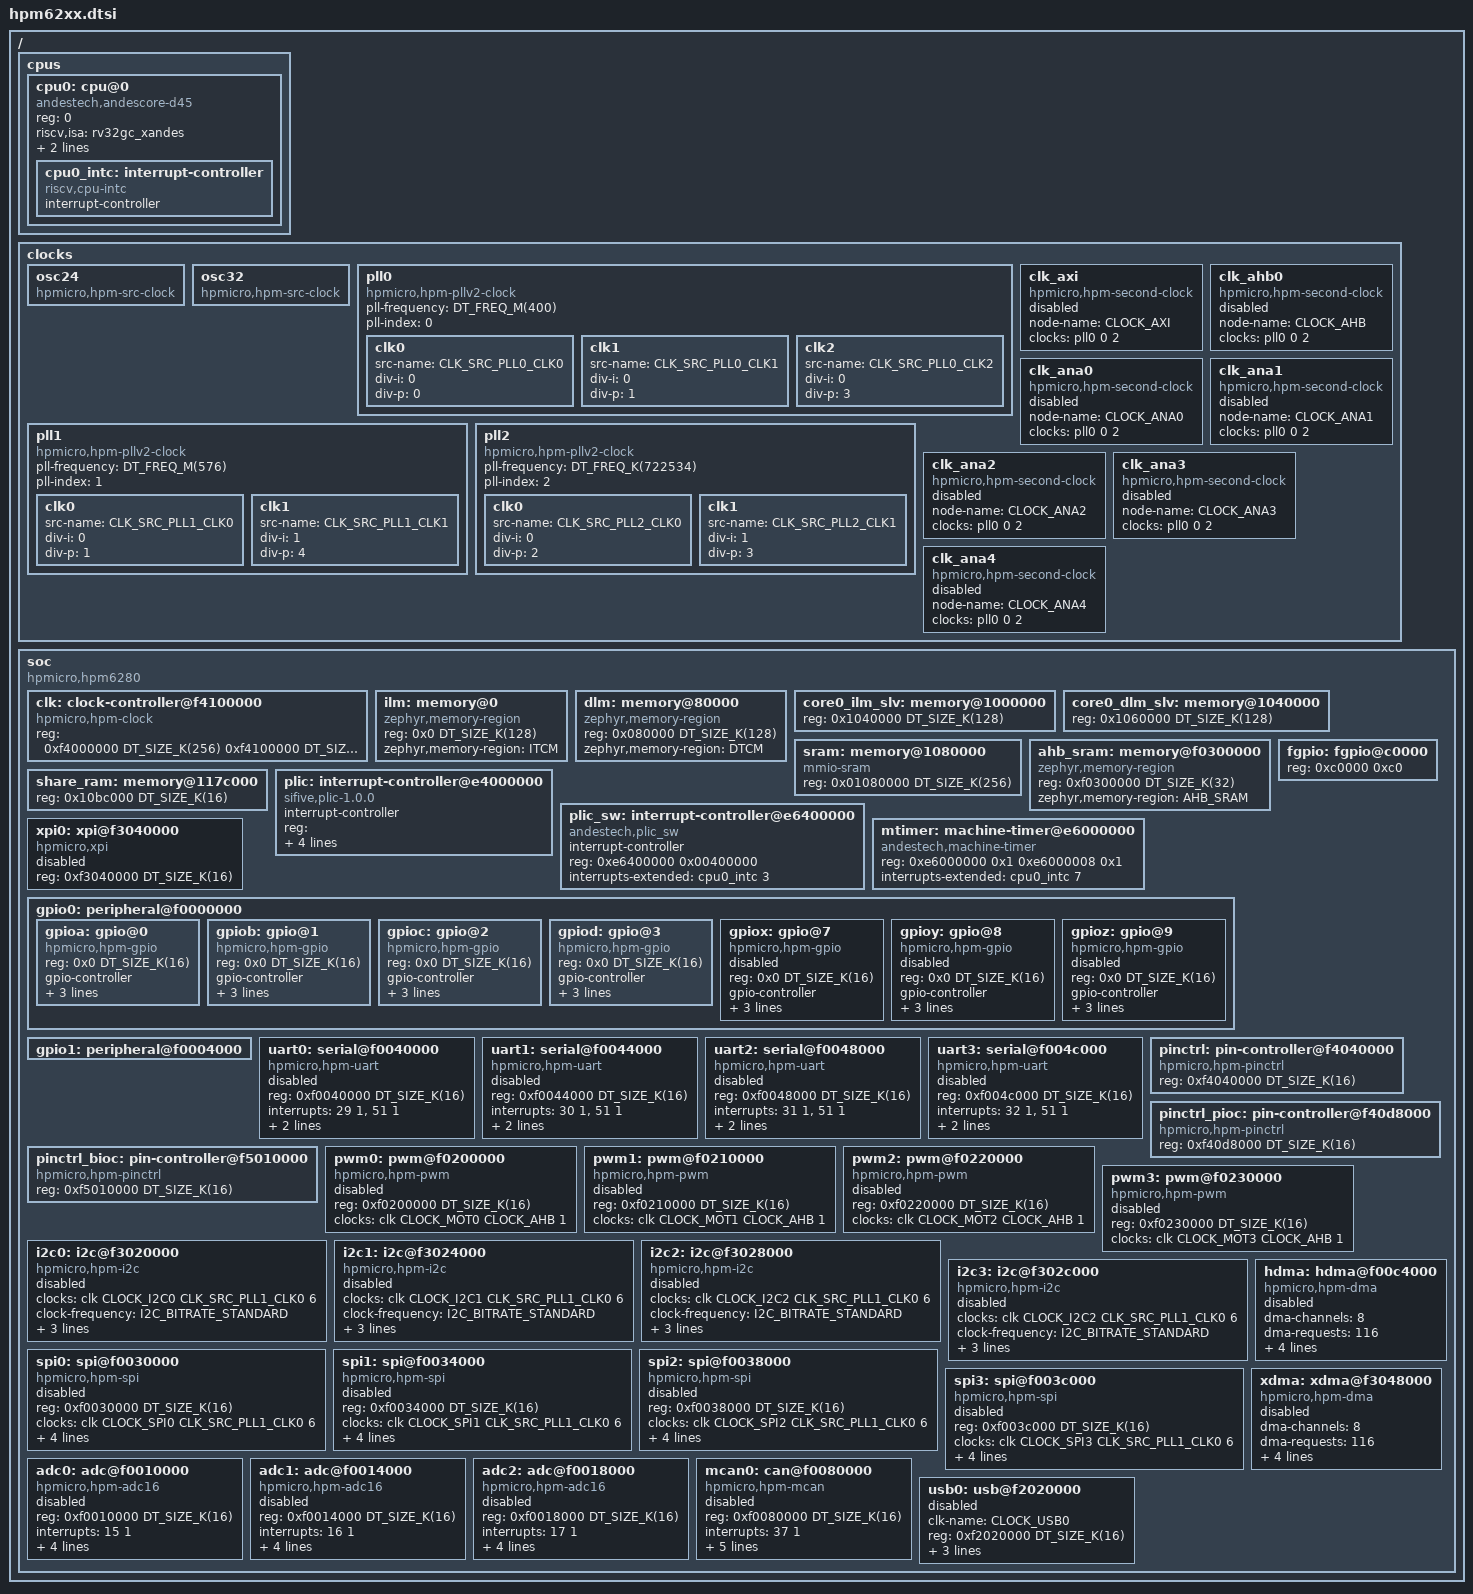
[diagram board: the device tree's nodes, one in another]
/*
 * Copyright 2023-2025 HPMicro
 * SPDX-License-Identifier: Apache-2.0
 */

/dts-v1/;
#include <zephyr/dt-bindings/gpio/gpio.h>
#include <zephyr/dt-bindings/i2c/i2c.h>
#include <zephyr/dt-bindings/pwm/pwm.h>
#include <dt-bindings/pwm/hpmicro-pwm-common.h>
#include <dt-bindings/clock/hpm6280-clocks.h>
#include <mem.h>
#include <freq.h>

/ {
    #address-cells = <1>;
    #size-cells = <1>;

    cpus {
        #address-cells = <1>;
        #size-cells = <0>;
        cpu0: cpu@0 {
            compatible = "andestech,andescore-d45", "riscv";
            reg = <0>;
            status = "okay";
            riscv,isa = "rv32gc_xandes";
            i-cache-line-size = <64>;
            d-cache-line-size = <64>;

            cpu0_intc: interrupt-controller {
                compatible = "riscv,cpu-intc";
                #address-cells = <0>;
                #interrupt-cells = <1>;
                interrupt-controller;
            };
        };
    };

    clocks {
        osc24: osc24 {
            #clock-cells = <2>;
            compatible = "hpmicro,hpm-src-clock";
        };

        osc32: osc32 {
            #clock-cells = <2>;
            compatible = "hpmicro,hpm-src-clock";
        };

        pll0: pll0 {
            #clock-cells = <2>;
            compatible = "hpmicro,hpm-pllv2-clock";
            pll-frequency = <DT_FREQ_M(400)>;
            pll-index = <0>;

            clk0 {
                src-name = <CLK_SRC_PLL0_CLK0>;
                div-i = <0>;
                div-p = <0>;
            };

            clk1 {
                src-name = <CLK_SRC_PLL0_CLK1>;
                div-i = <0>;
                div-p = <1>;
            };

            clk2 {
                src-name = <CLK_SRC_PLL0_CLK2>;
                div-i = <0>;
                div-p = <3>;
            };
        };

        pll1: pll1 {
            #clock-cells = <2>;
            compatible = "hpmicro,hpm-pllv2-clock";
            pll-frequency = <DT_FREQ_M(576)>;
            pll-index = <1>;

            clk0 {
                src-name = <CLK_SRC_PLL1_CLK0>;
                div-i = <0>;
                div-p = <1>;
            };

            clk1 {
                src-name = <CLK_SRC_PLL1_CLK1>;
                div-i = <1>;
                div-p = <4>;
            };
        };

        pll2: pll2 {
            #clock-cells = <2>;
            compatible = "hpmicro,hpm-pllv2-clock";
            pll-frequency = <DT_FREQ_K(722534)>;
            pll-index = <2>;

            clk0 {
                src-name = <CLK_SRC_PLL2_CLK0>;
                div-i = <0>;
                div-p = <2>;
            };

            clk1 {
                src-name = <CLK_SRC_PLL2_CLK1>;
                div-i = <1>;
                div-p = <3>;
            };
        };

        clk_axi: clk_axi {
            #clock-cells = <2>;
            compatible = "hpmicro,hpm-second-clock";
            node-name = <CLOCK_AXI>;
            clocks = <&pll0 0 2>;
            status = "disabled";
        };

        clk_ahb0: clk_ahb0 {
            #clock-cells = <2>;
            compatible = "hpmicro,hpm-second-clock";
            node-name = <CLOCK_AHB>;
            clocks = <&pll0 0 2>;
            status = "disabled";
        };

        clk_ana0: clk_ana0 {
            #clock-cells = <2>;
            compatible = "hpmicro,hpm-second-clock";
            node-name = <CLOCK_ANA0>;
            clocks = <&pll0 0 2>;
            status = "disabled";
        };

        clk_ana1: clk_ana1 {
            #clock-cells = <2>;
            compatible = "hpmicro,hpm-second-clock";
            node-name = <CLOCK_ANA1>;
            clocks = <&pll0 0 2>;
            status = "disabled";
        };

        clk_ana2: clk_ana2 {
            #clock-cells = <2>;
            compatible = "hpmicro,hpm-second-clock";
            node-name = <CLOCK_ANA2>;
            clocks = <&pll0 0 2>;
            status = "disabled";
        };

        clk_ana3: clk_ana3 {
            #clock-cells = <2>;
            compatible = "hpmicro,hpm-second-clock";
            node-name = <CLOCK_ANA3>;
            clocks = <&pll0 0 2>;
            status = "disabled";
        };

        clk_ana4: clk_ana4 {
            #clock-cells = <2>;
            compatible = "hpmicro,hpm-second-clock";
            node-name = <CLOCK_ANA4>;
            clocks = <&pll0 0 2>;
            status = "disabled";
        };
    };

    soc {
        #address-cells = <1>;
        #size-cells = <1>;
        compatible = "hpmicro,hpm6280";
        ranges;

        clk: clock-controller@f4100000 {
            compatible = "hpmicro,hpm-clock";
            reg = <0xf4000000 DT_SIZE_K(256)
                0xf4100000 DT_SIZE_K(16)>;
            reg-names = "sysctl", "pllv2";
            status = "okay";
            #clock-cells = <3>;
        };

        ilm: memory@0 {
            compatible = "zephyr,memory-region";
            reg = <0x0 DT_SIZE_K(128)>;
            zephyr,memory-region = "ITCM";
        };

        dlm: memory@80000 {
            compatible = "zephyr,memory-region";
            reg = <0x080000 DT_SIZE_K(128)>;
            zephyr,memory-region = "DTCM";
        };

        core0_ilm_slv: memory@1000000 {
            reg = <0x1040000 DT_SIZE_K(128)>;
        };

        core0_dlm_slv: memory@1040000 {
            reg = <0x1060000 DT_SIZE_K(128)>;
        };

        sram: memory@1080000 {
            compatible = "mmio-sram";
            reg = <0x01080000 DT_SIZE_K(256)>;
        };

        ahb_sram: memory@f0300000 {
            compatible = "zephyr,memory-region";
            reg = <0xf0300000 DT_SIZE_K(32)>;
            zephyr,memory-region = "AHB_SRAM";
        };

        share_ram: memory@117c000 {
            reg = <0x10bc000 DT_SIZE_K(16)>;
        };

        plic: interrupt-controller@e4000000 {
            compatible = "sifive,plic-1.0.0";
            #address-cells = <1>;
            #interrupt-cells = <2>;
            interrupt-controller;
            reg = <    0xe4000000 0x00001000
                0xe4002000 0x00000800
                0xe4200000 0x00010000 >;
            reg-names = "prio", "irq_en", "reg";
            riscv,max-priority = <255>;
            riscv,ndev = <1023>;
            interrupts-extended = <&cpu0_intc 11>;
        };

        plic_sw: interrupt-controller@e6400000 {
            compatible = "andestech,plic_sw";
            #address-cells = <1>;
            #interrupt-cells = <2>;
            interrupt-controller;
            reg = <0xe6400000 0x00400000>;
            interrupts-extended = <&cpu0_intc 3>;
        };

        mtimer: machine-timer@e6000000 {
            compatible = "andestech,machine-timer";
            reg = <0xe6000000 0x1
            0xe6000008 0x1>;
            interrupts-extended = <&cpu0_intc 7>;
        };

        fgpio: fgpio@c0000 {
            reg = <0xc0000 0xc0>;
        };

        xpi0: xpi@f3040000 {
            compatible = "hpmicro,xpi";
            reg = <0xf3040000 DT_SIZE_K(16)>;
            #address-cells = <1>;
            #size-cells = <1>;
            status = "disabled";
        };

        gpio0: peripheral@f0000000 {
            #address-cells = <1>;
            #size-cells = <1>;
            ranges = <0x0 0xf0000000 DT_SIZE_K(16)>;
        };

        gpio1: peripheral@f0004000 {
            #address-cells = <1>;
            #size-cells = <1>;
            ranges = <0x0 0xf0004000 DT_SIZE_K(16)>;
        };

        uart0: serial@f0040000 {
            compatible = "hpmicro,hpm-uart";
            reg = <0xf0040000 DT_SIZE_K(16)>;
            interrupts = <29 1>, <51 1>;
            interrupt-names = "uart", "idletimer";
            clocks = <&clk CLOCK_UART0 CLK_SRC_PLL1_CLK0 6>;
            interrupt-parent = <&plic>;
            status = "disabled";
        };

        uart1: serial@f0044000 {
            compatible = "hpmicro,hpm-uart";
            reg = <0xf0044000 DT_SIZE_K(16)>;
            interrupts = <30 1>, <51 1>;
            interrupt-names = "uart", "idletimer";
            clocks = <&clk CLOCK_UART1 CLK_SRC_PLL1_CLK0 6>;
            interrupt-parent = <&plic>;
            status = "disabled";
        };

        uart2: serial@f0048000 {
            compatible = "hpmicro,hpm-uart";
            reg = <0xf0048000 DT_SIZE_K(16)>;
            interrupts = <31 1>, <51 1>;
            interrupt-names = "uart", "idletimer";
            clocks = <&clk CLOCK_UART2 CLK_SRC_PLL1_CLK0 6>;
            interrupt-parent = <&plic>;
            status = "disabled";
        };

        uart3: serial@f004c000 {
            compatible = "hpmicro,hpm-uart";
            reg = <0xf004c000 DT_SIZE_K(16)>;
            interrupts = <32 1>, <51 1>;
            interrupt-names = "uart", "idletimer";
            clocks = <&clk CLOCK_UART3 CLK_SRC_PLL1_CLK0 6>;
            interrupt-parent = <&plic>;
            status = "disabled";
        };

        pinctrl: pin-controller@f4040000 {
            compatible = "hpmicro,hpm-pinctrl";
            reg = <0xf4040000 DT_SIZE_K(16)>;
            status = "okay";
        };

        pinctrl_pioc: pin-controller@f40d8000 {
            compatible = "hpmicro,hpm-pinctrl";
            reg = <0xf40d8000 DT_SIZE_K(16)>;
            status = "okay";
        };

        pinctrl_bioc: pin-controller@f5010000 {
            compatible = "hpmicro,hpm-pinctrl";
            reg = <0xf5010000 DT_SIZE_K(16)>;
            status = "okay";
        };

        pwm0: pwm@f0200000 {
            compatible = "hpmicro,hpm-pwm";
            reg = <0xf0200000 DT_SIZE_K(16)>;
            clocks = <&clk CLOCK_MOT0 CLOCK_AHB 1>;
            status = "disabled";
            #pwm-cells = <3>;
        };

        pwm1: pwm@f0210000 {
            compatible = "hpmicro,hpm-pwm";
            reg = <0xf0210000 DT_SIZE_K(16)>;
            clocks = <&clk CLOCK_MOT1 CLOCK_AHB 1>;
            status = "disabled";
            #pwm-cells = <3>;
        };

        pwm2: pwm@f0220000 {
            compatible = "hpmicro,hpm-pwm";
            reg = <0xf0220000 DT_SIZE_K(16)>;
            clocks = <&clk CLOCK_MOT2 CLOCK_AHB 1>;
            status = "disabled";
            #pwm-cells = <3>;
        };

        pwm3: pwm@f0230000 {
            compatible = "hpmicro,hpm-pwm";
            reg = <0xf0230000 DT_SIZE_K(16)>;
            clocks = <&clk CLOCK_MOT3 CLOCK_AHB 1>;
            status = "disabled";
            #pwm-cells = <3>;
        };

        i2c0: i2c@f3020000 {
            compatible = "hpmicro,hpm-i2c";
            #address-cells = <1>;
            #size-cells = <0>;
            clocks = <&clk CLOCK_I2C0 CLK_SRC_PLL1_CLK0 6>;
            clock-frequency = <I2C_BITRATE_STANDARD>;
            reg = <0xf3020000 DT_SIZE_K(16)>;
            interrupts = <53 1>;
            interrupt-parent = <&plic>;
            status = "disabled";
        };

        i2c1: i2c@f3024000 {
            compatible = "hpmicro,hpm-i2c";
            #address-cells = <1>;
            #size-cells = <0>;
            clocks = <&clk CLOCK_I2C1 CLK_SRC_PLL1_CLK0 6>;
            clock-frequency = <I2C_BITRATE_STANDARD>;
            reg = <0xf3024000 DT_SIZE_K(16)>;
            interrupts = <54 1>;
            interrupt-parent = <&plic>;
            status = "disabled";
        };

        i2c2: i2c@f3028000 {
            compatible = "hpmicro,hpm-i2c";
            #address-cells = <1>;
            #size-cells = <0>;
            clocks = <&clk CLOCK_I2C2 CLK_SRC_PLL1_CLK0 6>;
            clock-frequency = <I2C_BITRATE_STANDARD>;
            reg = <0xf3028000 DT_SIZE_K(16)>;
            interrupts = <55 1>;
            interrupt-parent = <&plic>;
            status = "disabled";
        };

        i2c3: i2c@f302c000 {
            compatible = "hpmicro,hpm-i2c";
            #address-cells = <1>;
            #size-cells = <0>;
            clocks = <&clk CLOCK_I2C2 CLK_SRC_PLL1_CLK0 6>;
            clock-frequency = <I2C_BITRATE_STANDARD>;
            reg = <0xf302c000 DT_SIZE_K(16)>;
            interrupts = <56 1>;
            interrupt-parent = <&plic>;
            status = "disabled";
        };

        spi0: spi@f0030000 {
            compatible = "hpmicro,hpm-spi";
            reg = <0xf0030000 DT_SIZE_K(16)>;
            clocks = <&clk CLOCK_SPI0 CLK_SRC_PLL1_CLK0 6>;
            interrupts = <25 1>;
            interrupt-parent = <&plic>;
            status = "disabled";
            #address-cells = <1>;
            #size-cells = <0>;
            cs-sck-delay = <3>;
            cs-minimum-high-time = <11>;
        };

        spi1: spi@f0034000 {
            compatible = "hpmicro,hpm-spi";
            reg = <0xf0034000 DT_SIZE_K(16)>;
            clocks = <&clk CLOCK_SPI1 CLK_SRC_PLL1_CLK0 6>;
            interrupts = <26 1>;
            interrupt-parent = <&plic>;
            status = "disabled";
            #address-cells = <1>;
            #size-cells = <0>;
            cs-sck-delay = <3>;
            cs-minimum-high-time = <11>;
        };

        spi2: spi@f0038000 {
            compatible = "hpmicro,hpm-spi";
            reg = <0xf0038000 DT_SIZE_K(16)>;
            clocks = <&clk CLOCK_SPI2 CLK_SRC_PLL1_CLK0 6>;
            interrupts = <27 1>;
            interrupt-parent = <&plic>;
            status = "disabled";
            #address-cells = <1>;
            #size-cells = <0>;
            cs-sck-delay = <3>;
            cs-minimum-high-time = <11>;
        };


        spi3: spi@f003c000 {
            compatible = "hpmicro,hpm-spi";
            reg = <0xf003c000 DT_SIZE_K(16)>;
            clocks = <&clk CLOCK_SPI3 CLK_SRC_PLL1_CLK0 6>;
            interrupts = <28 1>;
            interrupt-parent = <&plic>;
            status = "disabled";
            #address-cells = <1>;
            #size-cells = <0>;
            cs-sck-delay = <3>;
            cs-minimum-high-time = <11>;
        };

        hdma: hdma@f00c4000 {
            #dma-cells = <2>;
            compatible = "hpmicro,hpm-dma";
            dma-channels = <8>;
            dma-requests = <116>;
            reg = <0xf00c4000 DT_SIZE_K(16)>,
                <0xf00c0000 DT_SIZE_K(16)>; /* DMAMUX base */
            interrupts = <72 1>;
            interrupt-parent = <&plic>;
            status = "disabled";
        };

        xdma: xdma@f3048000 {
            #dma-cells = <2>;
            compatible = "hpmicro,hpm-dma";
            dma-channels = <8>;
            dma-requests = <116>;
            reg = <0xf3048000 DT_SIZE_K(16)>,
                <0xf00c0000 DT_SIZE_K(16)>; /* DMAMUX base */
            interrupts = <71 1>;
            interrupt-parent = <&plic>;
            status = "disabled";
        };

        adc0: adc@f0010000 {
            compatible = "hpmicro,hpm-adc16";
            reg = <0xf0010000 DT_SIZE_K(16)>;
            interrupts = <15 1>;
            interrupt-parent = <&plic>;
            clocks = <&clk CLOCK_ADC0 CLK_ADC_SRC_ANA0 1>, <&clk CLOCK_ANA0 CLK_SRC_PLL0_CLK0 2>;
            sample-time = <20>;
            status = "disabled";
            #io-channel-cells = <1>;
        };

        adc1: adc@f0014000 {
            compatible = "hpmicro,hpm-adc16";
            reg = <0xf0014000 DT_SIZE_K(16)>;
            interrupts = <16 1>;
            interrupt-parent = <&plic>;
            clocks = <&clk CLOCK_ADC1 CLK_ADC_SRC_ANA1 1>, <&clk CLOCK_ANA1 CLK_SRC_PLL0_CLK0 2>;
            sample-time = <20>;
            status = "disabled";
            #io-channel-cells = <1>;
        };

        adc2: adc@f0018000 {
            compatible = "hpmicro,hpm-adc16";
            reg = <0xf0018000 DT_SIZE_K(16)>;
            interrupts = <17 1>;
            interrupt-parent = <&plic>;
            clocks = <&clk CLOCK_ADC2 CLK_ADC_SRC_ANA2 1>, <&clk CLOCK_ANA2 CLK_SRC_PLL0_CLK0 2>;
            sample-time = <20>;
            status = "disabled";
            #io-channel-cells = <1>;
        };

        mcan0: can@f0080000 {
                compatible = "hpmicro,hpm-mcan";
                reg = <0xf0080000 DT_SIZE_K(16)>;
                interrupts = <37 1>;
                interrupt-parent = <&plic>;
                clk-name = <CLOCK_CAN0>;
                clk-source = <CLK_SRC_PLL1_CLK0>;
                clk-divider = <5>;
                bus-speed = <500000>;
                status = "disabled";
        };

        usb0: usb@f2020000 {
                clk-name = <CLOCK_USB0>;
                reg = <0xf2020000 DT_SIZE_K(16)>;
                interrupts = <74 1>;
                interrupt-parent = <&plic>;
                num-bidir-endpoints = <8>;
                status = "disabled";
        };
    };
};

&gpio0 {
    gpioa: gpio@0 {
        compatible = "hpmicro,hpm-gpio";
        reg = <0x0 DT_SIZE_K(16)>;
        gpio-controller;
        #gpio-cells = <2>;
        hpmicro-gpio-port = <0>;
        interrupts = <1 1>;
        interrupt-parent = <&plic>;
    };

    gpiob: gpio@1 {
        compatible = "hpmicro,hpm-gpio";
        reg = <0x0 DT_SIZE_K(16)>;
        gpio-controller;
        #gpio-cells = <2>;
        hpmicro-gpio-port = <1>;
        interrupts = <2 1>;
        interrupt-parent = <&plic>;
    };

    gpioc: gpio@2 {
        compatible = "hpmicro,hpm-gpio";
        reg = <0x0 DT_SIZE_K(16)>;
        gpio-controller;
        #gpio-cells = <2>;
        hpmicro-gpio-port = <2>;
        interrupts = <3 1>;
        interrupt-parent = <&plic>;
    };

    gpiod: gpio@3 {
        compatible = "hpmicro,hpm-gpio";
        reg = <0x0 DT_SIZE_K(16)>;
        gpio-controller;
        #gpio-cells = <2>;
        hpmicro-gpio-port = <3>;
        interrupts = <4 1>;
        interrupt-parent = <&plic>;
    };

    gpiox: gpio@7 {
        compatible = "hpmicro,hpm-gpio";
        reg = <0x0 DT_SIZE_K(16)>;
        gpio-controller;
        #gpio-cells = <2>;
        hpmicro-gpio-port = <13>;
        interrupt-parent = <&plic>;
        interrupts = <5 1>;
        status = "disabled";
    };

    gpioy: gpio@8 {
        compatible = "hpmicro,hpm-gpio";
        reg = <0x0 DT_SIZE_K(16)>;
        gpio-controller;
        #gpio-cells = <2>;
        hpmicro-gpio-port = <14>;
        interrupts = <6 1>;
        interrupt-parent = <&plic>;
        status = "disabled";
    };

    gpioz: gpio@9 {
        compatible = "hpmicro,hpm-gpio";
        reg = <0x0 DT_SIZE_K(16)>;
        gpio-controller;
        #gpio-cells = <2>;
        hpmicro-gpio-port = <15>;
        interrupts = <7 1>;
        interrupt-parent = <&plic>;
        status = "disabled";
    };
};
